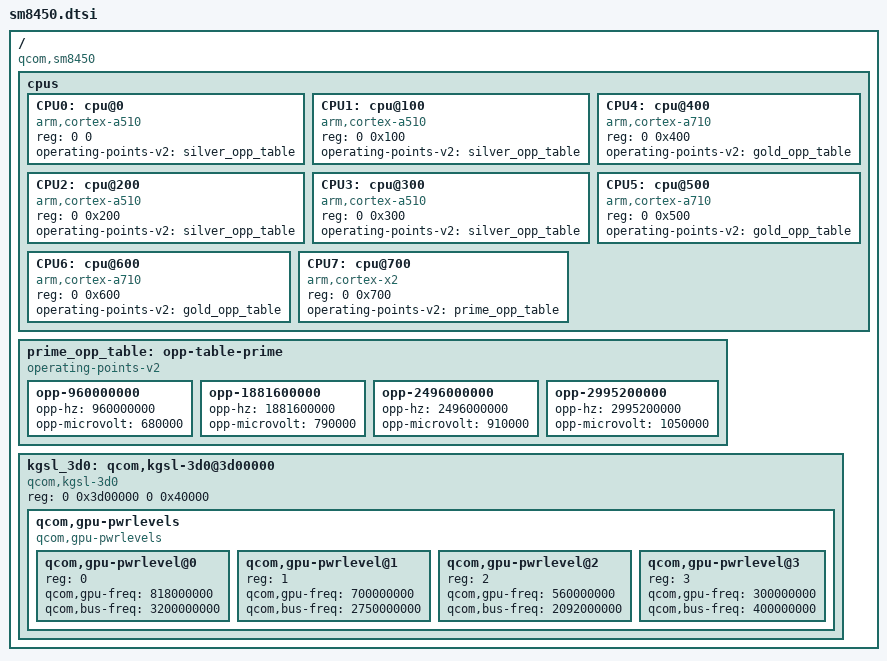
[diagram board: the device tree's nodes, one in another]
// SPDX-License-Identifier: GPL-2.0
/*
 * Qualcomm SM8450 (Snapdragon 8 Gen 1) Device Tree Source
 * Reference: Xiaomi 12 Pro / POCO F4 GT (Zeus / Ingres)
 * 4nm ARMv9 Cortex-X2 Tri-Cluster Architecture
 * Source: MiCode/Xiaomi_Kernel_OpenSource (zeus-s-oss)
 */

/ {
	compatible = "qcom,sm8450", "qcom,taro";

	cpus {
		#address-cells = <2>;
		#size-cells = <0>;

		/* Silver: 4x Cortex-A510 @ 1.80 GHz Cores 0-3 */
		CPU0: cpu@0 { device_type = "cpu"; compatible = "arm,cortex-a510"; reg = <0 0>; operating-points-v2 = <&silver_opp_table>; };
		CPU1: cpu@100 { device_type = "cpu"; compatible = "arm,cortex-a510"; reg = <0 0x100>; operating-points-v2 = <&silver_opp_table>; };
		CPU2: cpu@200 { device_type = "cpu"; compatible = "arm,cortex-a510"; reg = <0 0x200>; operating-points-v2 = <&silver_opp_table>; };
		CPU3: cpu@300 { device_type = "cpu"; compatible = "arm,cortex-a510"; reg = <0 0x300>; operating-points-v2 = <&silver_opp_table>; };

		/* Gold: 3x Cortex-A710 @ 2.50 GHz Cores 4-6 */
		CPU4: cpu@400 { device_type = "cpu"; compatible = "arm,cortex-a710"; reg = <0 0x400>; operating-points-v2 = <&gold_opp_table>; };
		CPU5: cpu@500 { device_type = "cpu"; compatible = "arm,cortex-a710"; reg = <0 0x500>; operating-points-v2 = <&gold_opp_table>; };
		CPU6: cpu@600 { device_type = "cpu"; compatible = "arm,cortex-a710"; reg = <0 0x600>; operating-points-v2 = <&gold_opp_table>; };

		/* Prime: 1x Cortex-X2 @ 3.00 GHz Core 7 */
		CPU7: cpu@700 { device_type = "cpu"; compatible = "arm,cortex-x2"; reg = <0 0x700>; operating-points-v2 = <&prime_opp_table>; };
	};

	prime_opp_table: opp-table-prime {
		compatible = "operating-points-v2";
		opp-960000000  { opp-hz = /bits/ 64 <960000000>;  opp-microvolt = <680000>; };
		opp-1881600000 { opp-hz = /bits/ 64 <1881600000>; opp-microvolt = <790000>; };
		opp-2496000000 { opp-hz = /bits/ 64 <2496000000>; opp-microvolt = <910000>; };
		opp-2995200000 { opp-hz = /bits/ 64 <2995200000>; opp-microvolt = <1050000>; };
	};

	/* Adreno 730 GPU */
	kgsl_3d0: qcom,kgsl-3d0@3d00000 {
		compatible = "qcom,kgsl-3d0", "qcom,kgsl-3d";
		reg = <0 0x3d00000 0 0x40000>;
		qcom,gpu-pwrlevels {
			#address-cells = <1>;
			#size-cells = <0>;
			compatible = "qcom,gpu-pwrlevels";

			qcom,gpu-pwrlevel@0 { reg = <0>; qcom,gpu-freq = <818000000>; qcom,bus-freq = <3200000000>; };
			qcom,gpu-pwrlevel@1 { reg = <1>; qcom,gpu-freq = <700000000>; qcom,bus-freq = <2750000000>; };
			qcom,gpu-pwrlevel@2 { reg = <2>; qcom,gpu-freq = <560000000>; qcom,bus-freq = <2092000000>; };
			qcom,gpu-pwrlevel@3 { reg = <3>; qcom,gpu-freq = <300000000>; qcom,bus-freq = <400000000>; };
		};
	};
};
